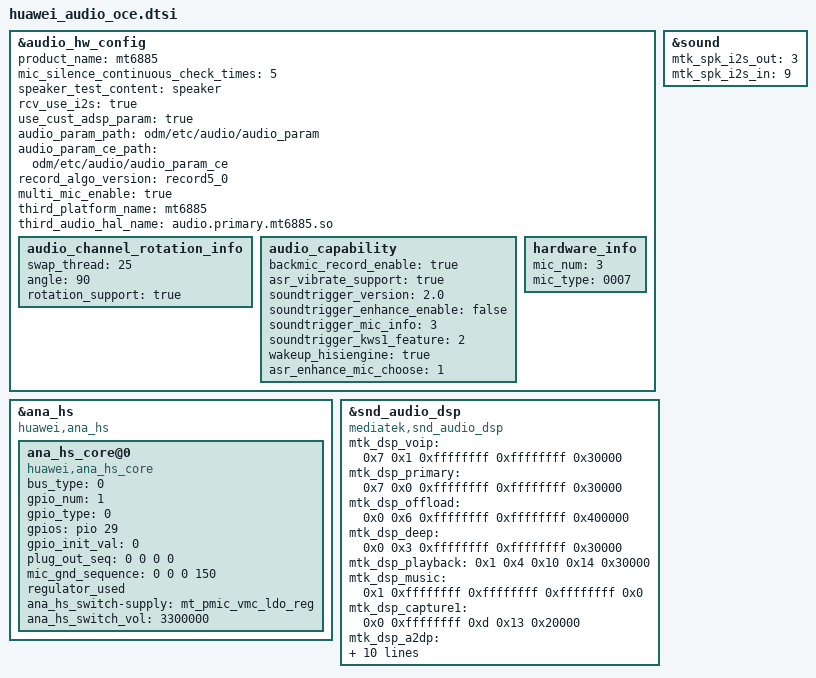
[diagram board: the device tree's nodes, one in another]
#include "device_boxid.dtsi"

&audio_hw_config {
	product_name = "mt6885";
	mic_silence_continuous_check_times = "5";
	speaker_test_content = "speaker";
	rcv_use_i2s = "true";
	use_cust_adsp_param = "true";
	audio_param_path = "odm/etc/audio/audio_param";
	audio_param_ce_path = "odm/etc/audio/audio_param_ce";
	record_algo_version = "record5_0";
	multi_mic_enable = "true";
	third_platform_name = "mt6885";
	third_audio_hal_name = "audio.primary.mt6885.so";
	audio_channel_rotation_info {
		swap_thread = "25";
		angle = "90";
		rotation_support = "true";
	};
	audio_capability {
		backmic_record_enable = "true";
		asr_vibrate_support = "true";
		/*
		sound trigger feature.
		false: this product doesn't support soundtrigger feature.
		2.0: this product supports the twice wakeup feature.
		*/
		soundtrigger_version = "2.0";
		soundtrigger_enhance_enable = "false";
		soundtrigger_mic_info = "3";
		/*
		bit0: node 900 optimization,  1:enab1e
		bit1:
			0: e2e disable
			1: e2e enable, must use hifi_6405_virtual_btn_devkit.img
		*/
		soundtrigger_kws1_feature = "2";
		/*
		max stream volume to replace Android default volume.
		*/
		/*
		use hisilicon wakeup engine.
		true: use hisilicon wakeup engine.
		false: DO NOT use hisilicon wakeup engine.
		*/
		wakeup_hisiengine = "true";
		asr_enhance_mic_choose = "1";
	};
	hardware_info {
		mic_num = "3";
		mic_type = "0007"; /* 0001 sub mic   0002 main mic   0004 sub mic2   0008 main mic2 */
	};
};

&ana_hs {
	compatible = "huawei,ana_hs";
	status = "ok";
	ana_hs_core@0 {
		compatible = "huawei,ana_hs_core";
		bus_type = <0>; /* 0: gpio,  1: i2c */

		/* if use gpio */
		gpio_num = <1>;
		gpio_type = <0>; /* 0: SOC,  1: codec */
		gpios = <&pio 29 0>;
		gpio_init_val = <0>;  /* 0: output low, 1: output high */

		/* plug_out sequence */
		plug_out_seq = <
			0 0 0 0
		>;
		/* mic_gnd_switch used gpio */
		mic_gnd_sequence = <
			0 0 0 150
		>;
		/* switch ana_hs usb using ldo */
		regulator_used;
		ana_hs_switch-supply = <&mt_pmic_vmc_ldo_reg>;
		ana_hs_switch_vol = <3300000>;
		status = "ok";
	};
};

&sound {
		mtk_spk_i2s_out = <3>;
		mtk_spk_i2s_in = <9>; /* 9 means 32bit, 0 means 24bit */
};

/* feature : $enable $dl_mem $ul_mem $ref_mem $size */
&snd_audio_dsp {
	compatible = "mediatek,snd_audio_dsp";
	mtk_dsp_voip = <0x7 0x1 0xffffffff 0xffffffff 0x30000>;
	mtk_dsp_primary = <0x7 0x0 0xffffffff 0xffffffff 0x30000>;
	mtk_dsp_offload = <0x0 0x6 0xffffffff 0xffffffff 0x400000>;
	mtk_dsp_deep = <0x0 0x3 0xffffffff 0xffffffff 0x30000>;
	mtk_dsp_playback = <0x1 0x4 0x10 0x14 0x30000>;
	mtk_dsp_music = <0x1 0xffffffff 0xffffffff 0xffffffff 0x0>;
	mtk_dsp_capture1 = <0x0 0xffffffff 0xd 0x13 0x20000>;
	mtk_dsp_a2dp = <0x0 0xffffffff 0xffffffff 0xffffffff 0x40000>;
	mtk_dsp_dataprovider = <0x0 0xffffffff 0xf 0xffffffff 0x30000>;
	mtk_dsp_call_final = <0x7 0x0 0x10 0x14 0x18000>;
	mtk_dsp_fast = <0x7 0x2 0xffffffff 0xffffffff 0x5000>;
	mtk_dsp_ktv = <0x1 0x8 0x12 0xffffffff 0x10000>;
	mtk_dsp_ver = <0x1>;
	swdsp_smartpa_process_enable = <0x7>;
	mtk_dsp_mem_afe = <0x1 0x40000>; /* always enable */
};
